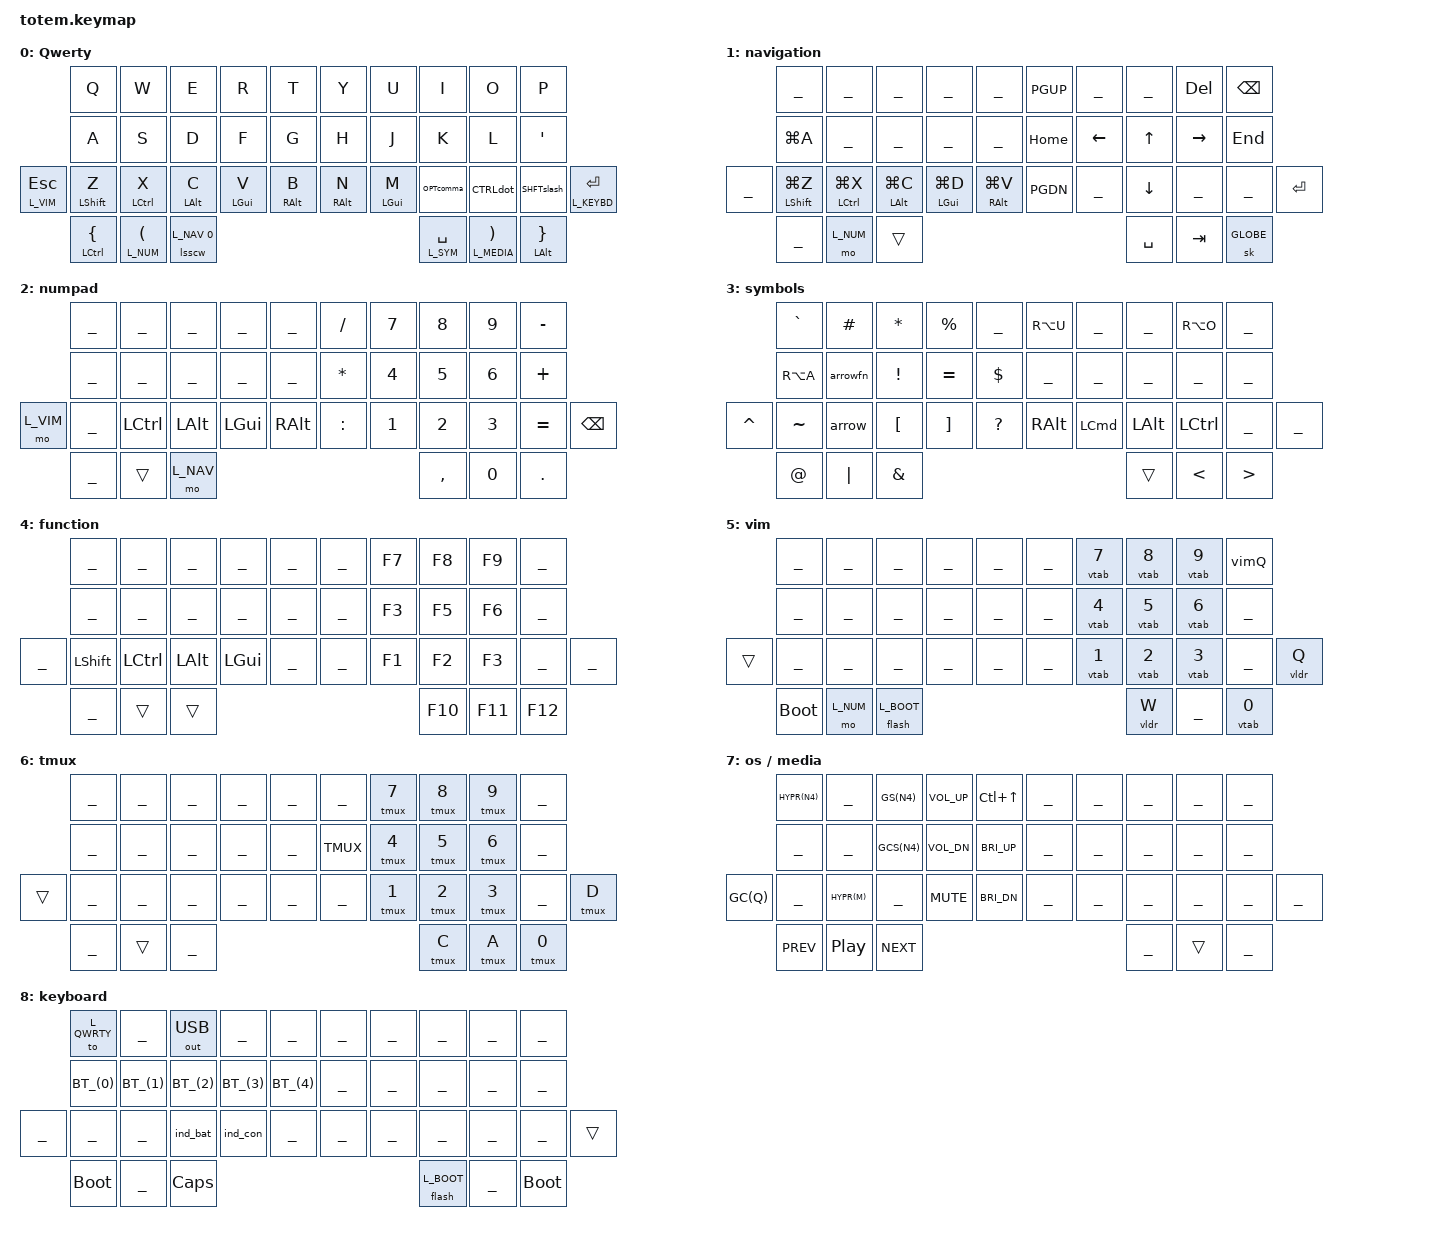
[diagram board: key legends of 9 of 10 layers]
//
//                  ▀▀▀▀▀     ▀▀▀▀▀          ▀▀█▀▀
//                  ▄▀▀▀▄  ▄  ▄▀▀▀▄  ▄  ▄▀▀▀▄  █  ▄▀▀▀▄
//                  █   █  █  █   █  █  █   █  █  █   █
//                   ▀▀▀   █   ▀▀▀   █   ▀▀▀   ▀   ▀▀▀
//                         █      ▄▄▄█▄▄▄    █   █
//                         ▀      █  █  █     █▄█
//                       ▀▀▀▀▀    █  █  █      ▀
//                                ▀  ▀  ▀
//
// ▄▄▄▄▄▄▄▄▄▄▄▄▄▄▄▄▄▄▄▄▄▄▄▄▄▄▄▄▄▄▄▄▄▄▄▄▄▄▄▄▄▄▄▄▄▄▄▄▄▄▄▄▄▄▄▄▄▄▄▄▄▄▄▄▄▄▄▄▄▄▄▄▄▄▄▄

#include <behaviors.dtsi>
#include <dt-bindings/zmk/bt.h>
#include <dt-bindings/zmk/keys.h>
#include <dt-bindings/zmk/outputs.h>
#include <behaviors/rgbled_widget.dtsi>  // needed to use the behaviors
#include "common.keys"

#define L_QWRTY 0
#define L_NAV   1
#define L_NUM   2
#define L_SYM   3
#define L_FUNC  4
#define L_VIM   5
#define L_TMUX  6
#define L_MEDIA 7
#define L_KEYBD 8
#define L_BOOT  9

/ {
    conditional_layers {
        compatible = "zmk,conditional-layers";
        func_layer {
            if-layers = <L_NAV L_NUM>;
            then-layer = <L_FUNC>;
        };
        tmux_layer {
            if-layers = <L_NUM L_VIM>;
            then-layer = <L_TMUX>;
        };
    };

    combos {
        compatible = "zmk,combos";
        combo_esc {
            timeout-ms = <50>;
            key-positions = <0 1>;
            bindings = <&kp ESC>;
        };
    };

    keymap {
        compatible = "zmk,keymap";
// ▄▄▄▄▄▄▄▄▄▄▄▄▄▄▄▄▄▄▄▄▄▄▄▄▄▄▄▄▄▄▄▄▄▄▄▄▄▄▄▄▄▄▄▄▄▄▄▄▄▄▄▄▄▄▄▄▄▄▄▄▄▄▄▄▄▄▄▄▄▄▄▄▄▄▄▄▄▄▄▄▄▄▄▄▄▄▄▄▄▄▄▄▄▄▄▄▄▄▄▄▄▄▄▄▄▄▄▄▄▄▄

        qwerty_layer {
//                       ┏━━━━━━━━━━━━━━━━━━━━━━━━━┓
            display-name = "Qwerty"                ;
//                       ┗━━━━━━━━━━━━━━━━━━━━━━━━━┛
//         ┏━━━━━━━┳━━━━━━━┳━━━━━━━┳━━━━━━━┳━━━━━━━┓             ┏━━━━━━━┳━━━━━━━┳━━━━━━━┳━━━━━━━┳━━━━━━━┓
//         ┃   Q   ┃   W   ┃   E   ┃   R   ┃   T   ┃             ┃   Y   ┃   U   ┃   I   ┃   O   ┃   P   ┃
//         ┣━━━━━━━╋━━━━━━━╋━━━━━━━╋━━━━━━━╋━━━━━━━┫             ┣━━━━━━━╋━━━━━━━╋━━━━━━━╋━━━━━━━╋━━━━━━━┫
//         ┃   A   ┃   S   ┃   D   ┃   F   ┃   G   ┃             ┃   H   ┃   J   ┃   K   ┃   L   ┃  ' "  ┃
// ┏━━━━━━━╋━━━━━━━╋━━━━━━━╋━━━━━━━╋━━━━━━━╋━━━━━━━┫             ┣━━━━━━━╋━━━━━━━╋━━━━━━━╋━━━━━━━╋━━━━━━━╋━━━━━━━┓
// ┃  ESC  ┃   Z   ┃   X   ┃   C   ┃   V   ┃   B   ┃             ┃   N   ┃   M   ┃  , ;  ┃  . :  ┃  / \  ┃ ENTER ┃
// ┃  vim  ┃ SHIFT ┃ CTRL  ┃  ALT  ┃  CMD  ┃ R ALT ┃             ┃ R ALT ┃  CMD  ┃  ALT  ┃ CTRL  ┃ SHIFT ┃ keybd ┃
// ┗━━━━━━━┻━━━━━━━┻━━━━━━━┻━━━━━┳━┻━━━━━┳━┻━━━━━┳━┻━━━━━┓ ┏━━━━━┻━┳━━━━━┻━┳━━━━━┻━┳━━━━━┻━━━━━━━┻━━━━━━━┻━━━━━━━┛
//                               ┃   {   ┃   (   ┃[SHIFT]┃ ┃ SPACE ┃   )   ┃   }   ┃
//                               ┃ CTRL  ┃  num  ┃  nav  ┃ ┃  sym  ┃ media ┃  ALT  ┃
//                               ┗━━━━━━━┻━━━━━━━┻━━━━━━━┛ ┗━━━━━━━┻━━━━━━━┻━━━━━━━┛
            bindings = <
//           ╷           ╷           ╷          ╷          ╷          ╷   ╷          ╷          ╷        ╷       ╷         ╷      ╷
              &kp Q       &kp W       &kp E      &kp R      &kp T          &kp Y      &kp U      &kp I    &kp O   &kp P
              &kp A       &kp S       &kp D      &kp F      &kp G          &kp H      &kp J      &kp K    &kp L   &kp SQT
&lt L_VIM ESC &mt LSHFT Z &mt LCTRL X &mt LALT C &mt LGUI V &mt RALT B     &mt RALT N &mt LGUI M OPTcomma CTRLdot SHFTslash &lt L_KEYBD RET
              &mt LCTRL LBRC   &lt L_NUM LPAR    &lsscw L_NAV 0            &lt L_SYM SPACE       &lt L_MEDIA RPAR &mt LALT RBRC
            >;
        };

// ▄▄▄▄▄▄▄▄▄▄▄▄▄▄▄▄▄▄▄▄▄▄▄▄▄▄▄▄▄▄▄▄▄▄▄▄▄▄▄▄▄▄▄▄▄▄▄▄▄▄▄▄▄▄▄▄▄▄▄▄▄▄▄▄▄▄▄▄▄▄▄▄▄▄▄▄▄▄▄▄▄▄▄▄▄▄▄▄▄▄▄▄▄▄▄▄▄▄▄▄▄▄▄▄▄▄▄▄▄▄▄

        nav_layer {
//                       ┏━━━━━━━━━━━━━━━━━━━━━━━━━┓
            display-name = "navigation"            ;
//                       ┗━━━━━━━━━━━━━━━━━━━━━━━━━┛
//         ┏━━━━━━━┳━━━━━━━┳━━━━━━━┳━━━━━━━┳━━━━━━━┓             ┏━━━━━━━┳━━━━━━━┳━━━━━━━┳━━━━━━━┳━━━━━━━┓
//         ┃       ┃       ┃       ┃       ┃       ┃             ┃ PG UP ┃       ┃       ┃  DEL  ┃ BKSPC ┃
//         ┣━━━━━━━╋━━━━━━━╋━━━━━━━╋━━━━━━━╋━━━━━━━┫             ┣━━━━━━━╋━━━━━━━╋━━━━━━━╋━━━━━━━╋━━━━━━━┫
//         ┃ cmd a ┃       ┃       ┃       ┃       ┃             ┃ HOME  ┃ LEFT  ┃  UP   ┃ RIGHT ┃  END  ┃
// ┏━━━━━━━╋━━━━━━━╋━━━━━━━╋━━━━━━━╋━━━━━━━╋━━━━━━━┫             ┣━━━━━━━╋━━━━━━━╋━━━━━━━╋━━━━━━━╋━━━━━━━╋━━━━━━━┓
// ┃       ┃ cmd z ┃ cmd x ┃ cmd c ┃ cmd d ┃ cmd v ┃             ┃ PG DN ┃       ┃ DOWN  ┃       ┃       ┃ ENTER ┃
// ┃       ┃ SHIFT ┃ CTRL  ┃  ALT  ┃  CMD  ┃ R ALT ┃             ┃       ┃       ┃       ┃       ┃       ┃       ┃
// ┗━━━━━━━┻━━━━━━━┻━━━━━━━┻━━━━━┳━┻━━━━━┳━┻━━━━━┳━┻━━━━━┓ ┏━━━━━┻━┳━━━━━┻━┳━━━━━┻━┳━━━━━┻━━━━━━━┻━━━━━━━┻━━━━━━━┛
//                               ┃       ┃ func  ┃  ###  ┃ ┃  SPC  ┃  TAB  ┃[GLOBE]┃
//                               ┗━━━━━━━┻━━━━━━━┻━━━━━━━┛ ┗━━━━━━━┻━━━━━━━┻━━━━━━━┛
            bindings = <
// ╷               ╷               ╷              ╷              ╷             ╷   ╷        ╷        ╷        ╷         ╷       ╷       ╷
    ___             ___             ___            ___            ___               &kp PGUP ___      ___      &kp DEL   &kp BSPC
    &kp LG(A)       ___             ___            ___            ___               &kp HOME &kp LEFT &kp UP   &kp RIGHT &kp END
___ &mt LSHFT LG(Z) &mt LCTRL LG(X) &mt LALT LG(C) &mt LGUI LG(D) &mt RALT LG(V)    &kp PGDN ___      &kp DOWN ___       ___     &kp RET
                                    ___            &mo L_NUM      &trans            &kp SPC  &kp TAB  &sk GLOBE
            >;
        };

// ▄▄▄▄▄▄▄▄▄▄▄▄▄▄▄▄▄▄▄▄▄▄▄▄▄▄▄▄▄▄▄▄▄▄▄▄▄▄▄▄▄▄▄▄▄▄▄▄▄▄▄▄▄▄▄▄▄▄▄▄▄▄▄▄▄▄▄▄▄▄▄▄▄▄▄▄▄▄▄▄▄▄▄▄▄▄▄▄▄▄▄▄▄▄▄▄▄▄▄▄▄▄▄▄▄▄▄▄▄▄▄

        num_layer {
//                       ┏━━━━━━━━━━━━━━━━━━━━━━━━━┓
            display-name = "numpad"                ;
//                       ┗━━━━━━━━━━━━━━━━━━━━━━━━━┛
//         ┏━━━━━━━┳━━━━━━━┳━━━━━━━┳━━━━━━━┳━━━━━━━┓             ┏━━━━━━━┳━━━━━━━┳━━━━━━━┳━━━━━━━┳━━━━━━━┓
//         ┃       ┃       ┃       ┃       ┃       ┃             ┃   /   ┃   7   ┃   8   ┃   9   ┃   -   ┃
//         ┣━━━━━━━╋━━━━━━━╋━━━━━━━╋━━━━━━━╋━━━━━━━┫             ┣━━━━━━━╋━━━━━━━╋━━━━━━━╋━━━━━━━╋━━━━━━━┫
//         ┃       ┃       ┃       ┃       ┃       ┃             ┃   *   ┃   4   ┃   5   ┃   6   ┃   +   ┃
// ┏━━━━━━━╋━━━━━━━╋━━━━━━━╋━━━━━━━╋━━━━━━━╋━━━━━━━┫             ┣━━━━━━━╋━━━━━━━╋━━━━━━━╋━━━━━━━╋━━━━━━━╋━━━━━━━┓
// ┃ tmux  ┃       ┃ CTRL  ┃  ALT  ┃  CMD  ┃ R ALT ┃             ┃   :   ┃   1   ┃   2   ┃   3   ┃   =   ┃ BSPC  ┃
// ┗━━━━━━━┻━━━━━━━┻━━━━━━━┻━━━━━┳━┻━━━━━┳━┻━━━━━┳━┻━━━━━┓ ┏━━━━━┻━┳━━━━━┻━┳━━━━━┻━┳━━━━━┻━━━━━━━┻━━━━━━━┻━━━━━━━┛
//                               ┃       ┃  ###  ┃ func  ┃ ┃   ,   ┃   0   ┃   .   ┃
//                               ┗━━━━━━━┻━━━━━━━┻━━━━━━━┛ ┗━━━━━━━┻━━━━━━━┻━━━━━━━┛
            bindings = <
//       ╷   ╷         ╷        ╷         ╷        ╷   ╷         ╷       ╷      ╷      ╷         ╷        ╷
          ___ ___       ___      ___       ___          &kp SLASH &kp N7  &kp N8 &kp N9 &kp MINUS
          ___ ___       ___      ___       ___          &kp STAR  &kp N4  &kp N5 &kp N6 &kp PLUS
&mo L_VIM ___ &kp LCTRL &kp LALT &kp LGUI  &kp RALT     &kp COLON &kp N1  &kp N2 &kp N3 &kp EQUAL &kp BSPC
                        ___      &trans    &mo L_NAV    &kp COMMA &kp N0  &kp DOT
            >;
        };

// ▄▄▄▄▄▄▄▄▄▄▄▄▄▄▄▄▄▄▄▄▄▄▄▄▄▄▄▄▄▄▄▄▄▄▄▄▄▄▄▄▄▄▄▄▄▄▄▄▄▄▄▄▄▄▄▄▄▄▄▄▄▄▄▄▄▄▄▄▄▄▄▄▄▄▄▄▄▄▄▄▄▄▄▄▄▄▄▄▄▄▄▄▄▄▄▄▄▄▄▄▄▄▄▄▄▄▄▄▄▄▄

        sym_layer {
//                       ┏━━━━━━━━━━━━━━━━━━━━━━━━━┓
            display-name = "symbols"               ;
//                       ┗━━━━━━━━━━━━━━━━━━━━━━━━━┛
//         ┏━━━━━━━┳━━━━━━━┳━━━━━━━┳━━━━━━━┳━━━━━━━┓             ┏━━━━━━━┳━━━━━━━┳━━━━━━━┳━━━━━━━┳━━━━━━━┓
//         ┃   `   ┃   #   ┃   *   ┃   %   ┃   _   ┃             ┃   Ü   ┃       ┃       ┃   Ö   ┃       ┃
//         ┣━━━━━━━╋━━━━━━━╋━━━━━━━╋━━━━━━━╋━━━━━━━┫             ┣━━━━━━━╋━━━━━━━╋━━━━━━━╋━━━━━━━╋━━━━━━━┫
//         ┃   Ä   ┃()=>{ }┃   !   ┃   =   ┃   $   ┃             ┃       ┃       ┃       ┃       ┃       ┃
// ┏━━━━━━━╋━━━━━━━╋━━━━━━━╋━━━━━━━╋━━━━━━━╋━━━━━━━┫             ┣━━━━━━━╋━━━━━━━╋━━━━━━━╋━━━━━━━╋━━━━━━━╋━━━━━━━┓
// ┃   ^   ┃   ~   ┃   =>  ┃   [   ┃   ]   ┃   ?   ┃             ┃ R ALT ┃  CMD  ┃  ALT  ┃ CTRL  ┃       ┃       ┃
// ┗━━━━━━━┻━━━━━━━┻━━━━━━━┻━━━━━┳━┻━━━━━┳━┻━━━━━┳━┻━━━━━┓ ┏━━━━━┻━┳━━━━━┻━┳━━━━━┻━┳━━━━━┻━━━━━━━┻━━━━━━━┻━━━━━━━┛
//                               ┃   @   ┃   |   ┃   &   ┃ ┃  ###  ┃   <   ┃   >   ┃
//                               ┗━━━━━━━┻━━━━━━━┻━━━━━━━┛ ┗━━━━━━━┻━━━━━━━┻━━━━━━━┛
            bindings = <
//       ╷         ╷        ╷        ╷         ╷         ╷   ╷         ╷        ╷        ╷         ╷   ╷   ╷
          &kp GRAVE &kp HASH &kp STAR &kp PRCNT &kp UNDER     &kp RA(U) ___      ___      &kp RA(O) ___
          &kp RA(A) &arrowfn &kp EXCL &kp EQUAL &kp DLLR      ___       ___      ___      ___       ___
&kp CARET &kp TILDE &arrow   &kp LBKT &kp RBKT  &kp QMARK     &kp RALT  &kp LCMD &kp LALT &kp LCTRL ___ ___
                             &kp AT   &kp PIPE  &kp AMPS      &trans    &kp LT   &kp GT
            >;
        };

// ▄▄▄▄▄▄▄▄▄▄▄▄▄▄▄▄▄▄▄▄▄▄▄▄▄▄▄▄▄▄▄▄▄▄▄▄▄▄▄▄▄▄▄▄▄▄▄▄▄▄▄▄▄▄▄▄▄▄▄▄▄▄▄▄▄▄▄▄▄▄▄▄▄▄▄▄▄▄▄▄▄▄▄▄▄▄▄▄▄▄▄▄▄▄▄▄▄▄▄▄▄▄▄▄▄▄▄▄▄▄▄

        func_layer {
//                       ┏━━━━━━━━━━━━━━━━━━━━━━━━━┓
            display-name = "function"              ;
//                       ┗━━━━━━━━━━━━━━━━━━━━━━━━━┛
//         ┏━━━━━━━┳━━━━━━━┳━━━━━━━┳━━━━━━━┳━━━━━━━┓             ┏━━━━━━━┳━━━━━━━┳━━━━━━━┳━━━━━━━┳━━━━━━━┓
//         ┃       ┃       ┃       ┃       ┃       ┃             ┃       ┃  F7   ┃  F8   ┃  F9   ┃       ┃
//         ┣━━━━━━━╋━━━━━━━╋━━━━━━━╋━━━━━━━╋━━━━━━━┫             ┣━━━━━━━╋━━━━━━━╋━━━━━━━╋━━━━━━━╋━━━━━━━┫
//         ┃       ┃       ┃       ┃       ┃       ┃             ┃       ┃  F4   ┃  F5   ┃  F6   ┃       ┃
// ┏━━━━━━━╋━━━━━━━╋━━━━━━━╋━━━━━━━╋━━━━━━━╋━━━━━━━┫             ┣━━━━━━━╋━━━━━━━╋━━━━━━━╋━━━━━━━╋━━━━━━━╋━━━━━━━┓
// ┃       ┃ SHIFT ┃ CTRL  ┃  ALT  ┃  CMD  ┃       ┃             ┃       ┃  F1   ┃  F2   ┃  F3   ┃       ┃       ┃
// ┗━━━━━━━┻━━━━━━━┻━━━━━━━┻━━━━━┳━┻━━━━━┳━┻━━━━━┳━┻━━━━━┓ ┏━━━━━┻━┳━━━━━┻━┳━━━━━┻━┳━━━━━┻━━━━━━━┻━━━━━━━┻━━━━━━━┛
//                               ┃       ┃  ###  ┃  ###  ┃ ┃  F10  ┃  F11  ┃  F12  ┃
//                               ┗━━━━━━━┻━━━━━━━┻━━━━━━━┛ ┗━━━━━━━┻━━━━━━━┻━━━━━━━┛
            bindings = <
// ╷         ╷         ╷        ╷        ╷      ╷   ╷       ╷       ╷       ╷      ╷   ╷   ╷
    ___       ___       ___      ___      ___        ___     &kp F7  &kp F8  &kp F9 ___
    ___       ___       ___      ___      ___        ___     &kp F3  &kp F5  &kp F6 ___
___ &kp LSHFT &kp LCTRL &kp LALT &kp LGUI ___        ___     &kp F1  &kp F2  &kp F3 ___ ___
                        ___      &trans   &trans     &kp F10 &kp F11 &kp F12
            >;
        };

// ▄▄▄▄▄▄▄▄▄▄▄▄▄▄▄▄▄▄▄▄▄▄▄▄▄▄▄▄▄▄▄▄▄▄▄▄▄▄▄▄▄▄▄▄▄▄▄▄▄▄▄▄▄▄▄▄▄▄▄▄▄▄▄▄▄▄▄▄▄▄▄▄▄▄▄▄▄▄▄▄▄▄▄▄▄▄▄▄▄▄▄▄▄▄▄▄▄▄▄▄▄▄▄▄▄▄▄▄▄▄▄

        vim_layer {
//                       ┏━━━━━━━━━━━━━━━━━━━━━━━━━┓
            display-name = "vim"                   ;
//                       ┗━━━━━━━━━━━━━━━━━━━━━━━━━┛
//         ┏━━━━━━━┳━━━━━━━┳━━━━━━━┳━━━━━━━┳━━━━━━━┓             ┏━━━━━━━┳━━━━━━━┳━━━━━━━┳━━━━━━━┳━━━━━━━┓
//         ┃       ┃       ┃       ┃       ┃       ┃             ┃       ┃ tab 7 ┃ tab 8 ┃ tab 9 ┃ QUIT! ┃
//         ┣━━━━━━━╋━━━━━━━╋━━━━━━━╋━━━━━━━╋━━━━━━━┫             ┣━━━━━━━╋━━━━━━━╋━━━━━━━╋━━━━━━━╋━━━━━━━┫
//         ┃       ┃       ┃       ┃       ┃       ┃             ┃       ┃ tab 4 ┃ tab 5 ┃ tab 6 ┃       ┃
// ┏━━━━━━━╋━━━━━━━╋━━━━━━━╋━━━━━━━╋━━━━━━━╋━━━━━━━┫             ┣━━━━━━━╋━━━━━━━╋━━━━━━━╋━━━━━━━╋━━━━━━━╋━━━━━━━┓
// ┃  ###  ┃       ┃       ┃       ┃       ┃       ┃             ┃       ┃ tab 1 ┃ tab 2 ┃ tab 3 ┃       ┃ exit  ┃
// ┗━━━━━━━┻━━━━━━━┻━━━━━━━┻━━━━━┳━┻━━━━━┳━┻━━━━━┳━┻━━━━━┓ ┏━━━━━┻━┳━━━━━┻━┳━━━━━┻━┳━━━━━┻━━━━━━━┻━━━━━━━┻━━━━━━━┛
//                               ┃ flash ┃ tmux  ┃ dongl ┃ ┃ save  ┃       ┃ tab10 ┃
//                               ┗━━━━━━━┻━━━━━━━┻━━━━━━━┛ ┗━━━━━━━┻━━━━━━━┻━━━━━━━┛
            bindings = <
//    ╷           ╷   ╷     ╷   ╷        ╷   ╷       ╷        ╷        ╷        ╷     ╷       ╷
       ___         ___ ___   ___ ___          ___     &vtab N7 &vtab N8 &vtab N9 &vimQ
       ___         ___ ___   ___ ___          ___     &vtab N4 &vtab N5 &vtab N6 ___
&trans ___         ___ ___   ___ ___          ___     &vtab N1 &vtab N2 &vtab N3 ___   &vldr Q
       &bootloader &mo L_NUM &flash L_BOOT     &vldr W ___      &vtab N0
            >;
        };

// ▄▄▄▄▄▄▄▄▄▄▄▄▄▄▄▄▄▄▄▄▄▄▄▄▄▄▄▄▄▄▄▄▄▄▄▄▄▄▄▄▄▄▄▄▄▄▄▄▄▄▄▄▄▄▄▄▄▄▄▄▄▄▄▄▄▄▄▄▄▄▄▄▄▄▄▄▄▄▄▄▄▄▄▄▄▄▄▄▄▄▄▄▄▄▄▄▄▄▄▄▄▄▄▄▄▄▄▄▄▄▄

        tmux_layer {
//                       ┏━━━━━━━━━━━━━━━━━━━━━━━━━┓
            display-name = "tmux"                  ;
//                       ┗━━━━━━━━━━━━━━━━━━━━━━━━━┛
//         ┏━━━━━━━┳━━━━━━━┳━━━━━━━┳━━━━━━━┳━━━━━━━┓             ┏━━━━━━━┳━━━━━━━┳━━━━━━━┳━━━━━━━┳━━━━━━━┓
//         ┃       ┃       ┃       ┃       ┃       ┃             ┃       ┃ tab 7 ┃ tab 8 ┃ tab 9 ┃       ┃
//         ┣━━━━━━━╋━━━━━━━╋━━━━━━━╋━━━━━━━╋━━━━━━━┫             ┣━━━━━━━╋━━━━━━━╋━━━━━━━╋━━━━━━━╋━━━━━━━┫
//         ┃       ┃       ┃       ┃       ┃       ┃             ┃ tmux- ┃ tab 4 ┃ tab 5 ┃ tab 6 ┃       ┃
// ┏━━━━━━━╋━━━━━━━╋━━━━━━━╋━━━━━━━╋━━━━━━━╋━━━━━━━┫             ┣━━━━━━━╋━━━━━━━╋━━━━━━━╋━━━━━━━╋━━━━━━━╋━━━━━━━┓
// ┃  ###  ┃       ┃       ┃       ┃       ┃       ┃             ┃       ┃ tab 1 ┃ tab 2 ┃ tab 3 ┃       ┃ close ┃
// ┗━━━━━━━┻━━━━━━━┻━━━━━━━┻━━━━━┳━┻━━━━━┳━┻━━━━━┳━┻━━━━━┓ ┏━━━━━┻━┳━━━━━┻━┳━━━━━┻━┳━━━━━┻━━━━━━━┻━━━━━━━┻━━━━━━━┛
//                               ┃       ┃  ###  ┃       ┃ ┃  new  ┃ name  ┃ tab10 ┃
//                               ┗━━━━━━━┻━━━━━━━┻━━━━━━━┛ ┗━━━━━━━┻━━━━━━━┻━━━━━━━┛
            bindings = <
//    ╷   ╷   ╷   ╷      ╷   ╷   ╷        ╷        ╷        ╷        ╷   ╷       ╷
       ___ ___ ___ ___    ___     ___      &tmux N7 &tmux N8 &tmux N9 ___
       ___ ___ ___ ___    ___     &kp TMUX &tmux N4 &tmux N5 &tmux N6 ___
&trans ___ ___ ___ ___    ___     ___      &tmux N1 &tmux N2 &tmux N3 ___ &tmux D
               ___ &trans ___     &tmux C  &tmux A  &tmux N0
            >;
        };

// ▄▄▄▄▄▄▄▄▄▄▄▄▄▄▄▄▄▄▄▄▄▄▄▄▄▄▄▄▄▄▄▄▄▄▄▄▄▄▄▄▄▄▄▄▄▄▄▄▄▄▄▄▄▄▄▄▄▄▄▄▄▄▄▄▄▄▄▄▄▄▄▄▄▄▄▄▄▄▄▄▄▄▄▄▄▄▄▄▄▄▄▄▄▄▄▄▄▄▄▄▄▄▄▄▄▄▄▄▄▄▄▄▄▄▄▄▄▄

        media_layer {
//                       ┏━━━━━━━━━━━━━━━━━━━━━━━━━━━━━━━┓
            display-name = "os / media"                  ;
//                       ┗━━━━━━━━━━━━━━━━━━━━━━━━━━━━━━━┛
//          ┏━━━━━━━━┳━━━━━━━━┳━━━━━━━━┳━━━━━━━━┳━━━━━━━━┓              ┏━━━━━━━┳━━━━━━━┳━━━━━━━┳━━━━━━━┳━━━━━━━┓
//          ┃ launch ┃        ┃ screen ┃ volume ┃ mssion ┃              ┃       ┃       ┃       ┃       ┃       ┃
//          ┃  pad   ┃        ┃  file  ┃   up   ┃ contrl ┃              ┃       ┃       ┃       ┃       ┃       ┃
//          ┣━━━━━━━━╋━━━━━━━━╋━━━━━━━━╋━━━━━━━━╋━━━━━━━━┫              ┣━━━━━━━╋━━━━━━━╋━━━━━━━╋━━━━━━━╋━━━━━━━┫
//          ┃        ┃        ┃ screen ┃ volume ┃ screen ┃              ┃       ┃       ┃       ┃       ┃       ┃
//          ┃        ┃        ┃  copy  ┃  down  ┃ bright ┃              ┃       ┃       ┃       ┃       ┃       ┃
// ┏━━━━━━━━╋━━━━━━━━╋━━━━━━━━╋━━━━━━━━╋━━━━━━━━╋━━━━━━━━┫              ┣━━━━━━━╋━━━━━━━╋━━━━━━━╋━━━━━━━╋━━━━━━━╋━━━━━━━┓
// ┃ screen ┃        ┃  mic   ┃        ┃        ┃ screen ┃              ┃       ┃       ┃       ┃       ┃       ┃       ┃
// ┃  lock  ┃        ┃  mute  ┃        ┃  mute  ┃ dimmer ┃              ┃       ┃       ┃       ┃       ┃       ┃       ┃
// ┗━━━━━━━━┻━━━━━━━━┻━━━━━━━━┻━━━━━━┳━┻━━━━━━┳━┻━━━━━━┳━┻━━━━━━┓ ┏━━━━━┻━┳━━━━━┻━┳━━━━━┻━┳━━━━━┻━━━━━━━┻━━━━━━━┻━━━━━━━┛
//                                   ┃  prev  ┃  play  ┃  next  ┃ ┃       ┃  ###  ┃       ┃
//                                   ┗━━━━━━━━┻━━━━━━━━┻━━━━━━━━┛ ┗━━━━━━━┻━━━━━━━┻━━━━━━━┛
            bindings = <
//   ╷        ╷       ╷       ╷          ╷          ╷   ╷   ╷   ╷   ╷   ╷   ╷   ╷
      HYPR(N4) ___     GS(N4)  VOL_UP     &kp LC(UP)     ___ ___ ___ ___ ___
      ___      ___     GCS(N4) VOL_DN     BRI_UP         ___ ___ ___ ___ ___
GC(Q) ___      HYPR(M) ___     &kp K_MUTE BRI_DN         ___ ___ ___ ___ ___ ___
      &kp C_PREV       &kp C_PLAY_PAUSE   &kp C_NEXT     ___ &trans  ___
            >;
        };

// ▄▄▄▄▄▄▄▄▄▄▄▄▄▄▄▄▄▄▄▄▄▄▄▄▄▄▄▄▄▄▄▄▄▄▄▄▄▄▄▄▄▄▄▄▄▄▄▄▄▄▄▄▄▄▄▄▄▄▄▄▄▄▄▄▄▄▄▄▄▄▄▄▄▄▄▄▄▄▄▄▄▄▄▄▄▄▄▄▄▄▄▄▄▄▄▄▄▄▄▄▄▄▄▄▄▄▄▄▄▄▄

        keyboard_layer {
//                       ┏━━━━━━━━━━━━━━━━━━━━━━━━━┓
            display-name = "keyboard"              ;
//                       ┗━━━━━━━━━━━━━━━━━━━━━━━━━┛
//         ┏━━━━━━━┳━━━━━━━┳━━━━━━━┳━━━━━━━┳━━━━━━━┓             ┏━━━━━━━┳━━━━━━━┳━━━━━━━┳━━━━━━━┳━━━━━━━┓
//         ┃ qwrty ┃       ┃  usb  ┃       ┃       ┃             ┃       ┃       ┃       ┃       ┃       ┃
//         ┣━━━━━━━╋━━━━━━━╋━━━━━━━╋━━━━━━━╋━━━━━━━┫             ┣━━━━━━━╋━━━━━━━╋━━━━━━━╋━━━━━━━╋━━━━━━━┫
//         ┃  BT1  ┃  BT2  ┃  BT3  ┃  BT4  ┃  BT5  ┃             ┃       ┃       ┃       ┃       ┃       ┃
// ┏━━━━━━━╋━━━━━━━╋━━━━━━━╋━━━━━━━╋━━━━━━━╋━━━━━━━┫             ┣━━━━━━━╋━━━━━━━╋━━━━━━━╋━━━━━━━╋━━━━━━━╋━━━━━━━┓
// ┃       ┃       ┃       ┃ i bat ┃ i con ┃       ┃             ┃       ┃       ┃       ┃       ┃       ┃  ###  ┃
// ┗━━━━━━━┻━━━━━━━┻━━━━━━━┻━━━━━┳━┻━━━━━┳━┻━━━━━┳━┻━━━━━┓ ┏━━━━━┻━┳━━━━━┻━┳━━━━━┻━┳━━━━━┻━━━━━━━┻━━━━━━━┻━━━━━━━┛
//                               ┃ flash ┃       ┃ CAPS  ┃ ┃ dongl ┃       ┃ flash ┃
//                               ┗━━━━━━━┻━━━━━━━┻━━━━━━━┛ ┗━━━━━━━┻━━━━━━━┻━━━━━━━┛
            bindings = <
// ╷           ╷      ╷            ╷           ╷            ╷   ╷             ╷   ╷           ╷   ╷   ╷           ╷
    &to L_QWRTY ___    &out OUT_USB ___         ___              ___           ___ ___         ___ ___
    BT_(0)      BT_(1) BT_(2)       BT_(3)      BT_(4)           ___           ___ ___         ___ ___
___ ___         ___    &ind_bat     &ind_con    ___              ___           ___ ___         ___ ___ &trans
                       &bootloader  ___         &kp CAPSLOCK     &flash L_BOOT ___ &bootloader
            >;
        };

// ▄▄▄▄▄▄▄▄▄▄▄▄▄▄▄▄▄▄▄▄▄▄▄▄▄▄▄▄▄▄▄▄▄▄▄▄▄▄▄▄▄▄▄▄▄▄▄▄▄▄▄▄▄▄▄▄▄▄▄▄▄▄▄▄▄▄▄▄▄▄▄▄▄▄▄▄▄▄▄▄▄▄▄▄▄▄▄▄▄▄▄▄▄▄▄▄▄▄▄▄▄▄▄▄▄▄▄▄▄▄▄

        bootloader_layer {
//                       ┏━━━━━━━━━━━━━━━━━━━━━━━━━┓
            display-name = "flash mode"            ;
//                       ┗━━━━━━━━━━━━━━━━━━━━━━━━━┛
//          This layer is just to get the oled to display the "layer name" immediately before it enters
//          boot loader mode and stops responding to any other keypresses.
//          Although "bindings" is required, none of these actually do anything.
            bindings = < &bootloader >;
        };

    };
};

// vim: expandtab softtabstop=4 shiftwidth=4 filetype=devicetree
